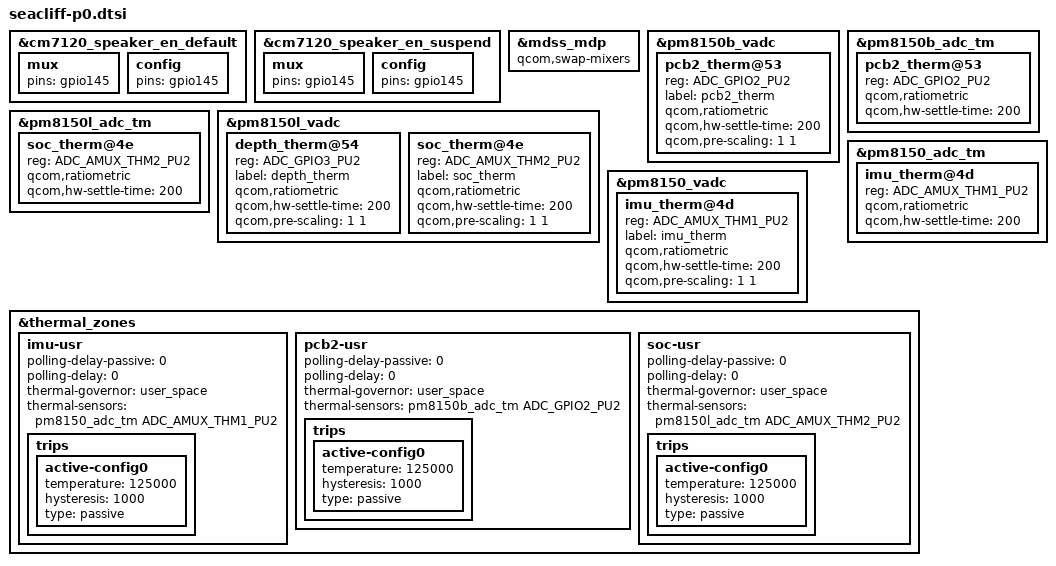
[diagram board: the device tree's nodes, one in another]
#include <dt-bindings/clock/qcom,gcc-kona.h>
#include <dt-bindings/clock/qcom,camcc-kona.h>
#include <dt-bindings/clock/qcom,rpmh.h>
#include <dt-bindings/interrupt-controller/arm-gic.h>

#include "seacliff-pop.dtsi"
#include "seacliff-qca6390.dtsi"

&cm7120_speaker_en_default {
	mux {
		pins = "gpio145";
	};

	config {
		pins = "gpio145";
	};
};

&cm7120_speaker_en_suspend {
	mux {
		pins = "gpio145";
	};

	config {
		pins = "gpio145";
	};
};

&mdss_mdp {
	qcom,swap-mixers;
};

&pm8150b_vadc {
	pcb2_therm@53 {
		reg = <ADC_GPIO2_PU2>;
		label = "pcb2_therm";
		qcom,ratiometric;
		qcom,hw-settle-time = <200>;
		qcom,pre-scaling = <1 1>;
	};
};

&pm8150b_adc_tm {
	pcb2_therm@53 {
		reg = <ADC_GPIO2_PU2>;
		qcom,ratiometric;
		qcom,hw-settle-time = <200>;
	};
};

&pm8150l_adc_tm {
	soc_therm@4e {
		reg = <ADC_AMUX_THM2_PU2>;
		qcom,ratiometric;
		qcom,hw-settle-time = <200>;
	};
};

&pm8150l_vadc {
	depth_therm@54 {
		reg = <ADC_GPIO3_PU2>;
		label = "depth_therm";
		qcom,ratiometric;
		qcom,hw-settle-time = <200>;
		qcom,pre-scaling = <1 1>;
	};

	soc_therm@4e {
		reg = <ADC_AMUX_THM2_PU2>;
		label = "soc_therm";
		qcom,ratiometric;
		qcom,hw-settle-time = <200>;
		qcom,pre-scaling = <1 1>;
	};
};

&pm8150_adc_tm {
	imu_therm@4d {
		reg = <ADC_AMUX_THM1_PU2>;
		qcom,ratiometric;
		qcom,hw-settle-time = <200>;
	};
};

&pm8150_vadc {
	imu_therm@4d {
		reg = <ADC_AMUX_THM1_PU2>;
		label = "imu_therm";
		qcom,ratiometric;
		qcom,hw-settle-time = <200>;
		qcom,pre-scaling = <1 1>;
	};
};

&thermal_zones {
	imu-usr {
		polling-delay-passive = <0>;
		polling-delay = <0>;
		thermal-governor = "user_space";
		thermal-sensors = <&pm8150_adc_tm ADC_AMUX_THM1_PU2>;
		trips {
			active-config0 {
				temperature = <125000>;
				hysteresis = <1000>;
				type = "passive";
			};
		};
	};

	pcb2-usr {
		polling-delay-passive = <0>;
		polling-delay = <0>;
		thermal-governor = "user_space";
		thermal-sensors = <&pm8150b_adc_tm ADC_GPIO2_PU2>;
		trips {
			active-config0 {
				temperature = <125000>;
				hysteresis = <1000>;
				type = "passive";
			};
		};
	};

	soc-usr {
		polling-delay-passive = <0>;
		polling-delay = <0>;
		thermal-governor = "user_space";
		thermal-sensors = <&pm8150l_adc_tm ADC_AMUX_THM2_PU2>;
		trips {
			active-config0 {
				temperature = <125000>;
				hysteresis = <1000>;
				type = "passive";
			};
		};
	};
};
